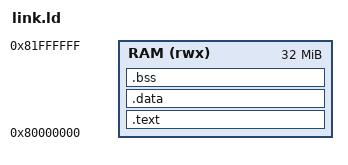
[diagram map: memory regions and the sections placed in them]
OUTPUT_FORMAT("elf32-littleriscv")
OUTPUT_ARCH(riscv)

ENTRY(_start)

MEMORY
{
    RAM (rwx) : ORIGIN = 0x80000000, LENGTH = 32M
}

SECTIONS
{
    .text :
    {
        *(.text.start)
        *(.text*)
        *(.rodata*)
        *(.srodata*)
    } > RAM

    .data :
    {
        *(.data*)
        *(.sdata*)
    } > RAM

    .bss :
    {
        _bss_start = .;
        *(.bss*)
        *(.sbss*)
        *(COMMON)
        _bss_end = .;
    } > RAM

    . = ALIGN(16);
    _heap_start = .;
    _heap_end = ORIGIN(RAM) + LENGTH(RAM) - 0x10000;
    _sp_top = ORIGIN(RAM) + LENGTH(RAM);
}
